CM_ "AUTOGENERATED FILE, DO NOT EDIT"

CM_ "Imported file _comma.dbc starts here"
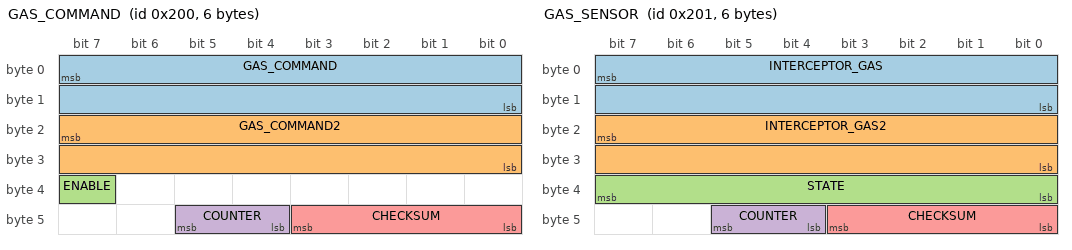
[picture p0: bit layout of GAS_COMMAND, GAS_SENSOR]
BO_ 512 GAS_COMMAND: 6 EON
 SG_ GAS_COMMAND : 7|16@0+ (0.253984064,-83.3) [0|1] "" INTERCEPTOR
 SG_ GAS_COMMAND2 : 23|16@0+ (0.126992032,-83.3) [0|1] "" INTERCEPTOR
 SG_ ENABLE : 39|1@0+ (1,0) [0|1] "" INTERCEPTOR
 SG_ COUNTER : 45|2@0+ (1,0) [0|3] "" INTERCEPTOR
 SG_ CHECKSUM : 43|4@0+ (1,0) [0|3] "" INTERCEPTOR

BO_ 513 GAS_SENSOR: 6 INTERCEPTOR
 SG_ INTERCEPTOR_GAS : 7|16@0+ (0.253984064,-83.3) [0|1] "" EON
 SG_ INTERCEPTOR_GAS2 : 23|16@0+ (0.126992032,-83.3) [0|1] "" EON
 SG_ STATE : 39|8@0+ (1,0) [0|255] "" EON
 SG_ COUNTER : 45|2@0+ (1,0) [0|3] "" EON
 SG_ CHECKSUM : 43|4@0+ (1,0) [0|3] "" EON

VAL_ 513 STATE 5 "FAULT_TIMEOUT" 4 "FAULT_STARTUP" 3 "FAULT_SCE" 2 "FAULT_SEND" 1 "FAULT_BAD_CHECKSUM" 0 "NO_FAULT" ;

CM_ "Imported file _honda_2017.dbc starts here"
VERSION ""

NS_ :

BU_: PCM MACC ABS EPS EON XXX

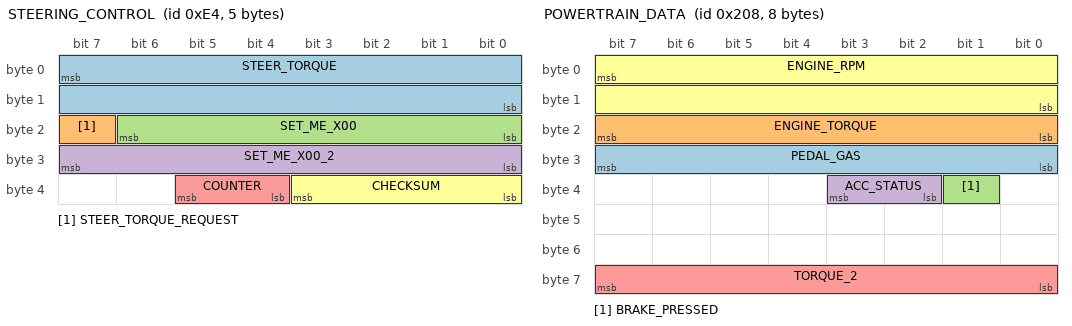
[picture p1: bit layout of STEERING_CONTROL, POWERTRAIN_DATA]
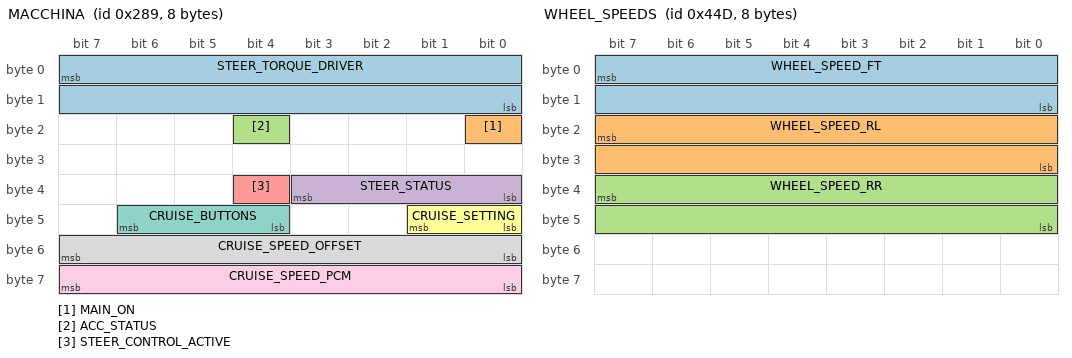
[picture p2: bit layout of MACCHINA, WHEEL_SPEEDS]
BO_ 228 STEERING_CONTROL: 5 ADAS
 SG_ STEER_TORQUE : 7|16@0- (1,0) [-3840|3840] "" EPS
 SG_ STEER_TORQUE_REQUEST : 23|1@0+ (1,0) [0|1] "" EPS
 SG_ SET_ME_X00 : 22|7@0+ (1,0) [0|127] "" EPS
 SG_ SET_ME_X00_2 : 31|8@0+ (1,0) [0|0] "" EPS
 SG_ COUNTER : 37|2@0+ (1,0) [0|3] "" EPS
 SG_ CHECKSUM : 35|4@0+ (1,0) [0|15] "" EPS

BO_ 520 POWERTRAIN_DATA: 8 PCM
 SG_ PEDAL_GAS : 24|8@1+ (1,0) [0|255] "" EON
 SG_ ENGINE_TORQUE : 23|8@0- (0.5,100) [0|255] "Nm" EON
 SG_ BRAKE_PRESSED : 33|1@0+ (1,0) [0|1] "" EON
 SG_ ACC_STATUS : 34|2@1+ (1,0) [0|3] "" EON
 SG_ TORQUE_2 : 56|8@1+ (0.5,100) [0|255] "" EON
 SG_ ENGINE_RPM : 7|16@0+ (0.15,0) [0|65535] "rpm" EON

 BO_ 649 MACCHINA: 8 MACC
 SG_ STEER_TORQUE_DRIVER : 7|16@0- (1,0) [-31000|31000] "" EON
 SG_ MAIN_ON : 16|1@0+ (1,0) [0|1] "" EON
 SG_ ACC_STATUS : 20|1@0+ (1,0) [0|1] "" EON
 SG_ STEER_STATUS : 35|4@0+ (1,0) [0|15] "" EON
 SG_ STEER_CONTROL_ACTIVE : 36|1@0+ (1,0) [0|1] "" EON
 SG_ CRUISE_SETTING: 41|2@0+ (1,0) [0|3] "" EON
 SG_ CRUISE_BUTTONS: 46|3@0+ (1,0) [0|7] "" EON
 SG_ CRUISE_SPEED_OFFSET: 55|8@0- (0.1,0) [-128|127] "kph" EON
 SG_ CRUISE_SPEED_PCM: 63|8@0+ (1,0) [0|255] "kph?" EON

BO_ 1101 WHEEL_SPEEDS: 8 PCM
 SG_ WHEEL_SPEED_FT : 7|16@0+ (0.01,0) [0|65535] "km/h" EON
 SG_ WHEEL_SPEED_RL : 23|16@0+ (0.01,0) [0|65535] "kph" EON
 SG_ WHEEL_SPEED_RR : 39|16@0+ (0.01,0) [0|65535] "kph" EON

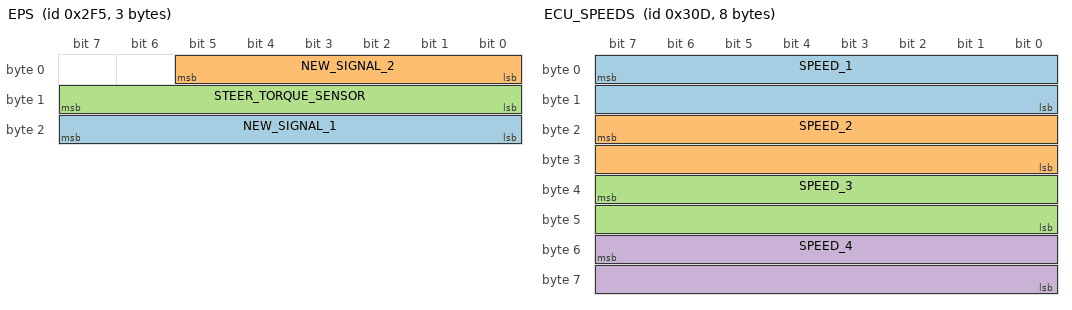
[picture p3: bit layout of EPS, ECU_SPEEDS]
BO_ 757 EPS: 3 EPS
 SG_ NEW_SIGNAL_1 : 23|8@0+ (1,0) [0|255] "" EON
 SG_ NEW_SIGNAL_2 : 0|6@1- (1,0) [0|3] "" EON
 SG_ STEER_TORQUE_SENSOR : 8|8@1- (1,0) [0|255] "Nm" EON

BO_ 781 ECU_SPEEDS: 8 PCM
 SG_ SPEED_1 : 7|16@0+ (0.01,0) [0|65535] "km/h" EON
 SG_ SPEED_2 : 23|16@0+ (0.01,0) [0|65535] "km/h" EON
 SG_ SPEED_3 : 39|16@0+ (0.01,0) [0|65535] "km/h" EON
 SG_ SPEED_4 : 55|16@0+ (0.01,0) [0|65535] "km/h" EON

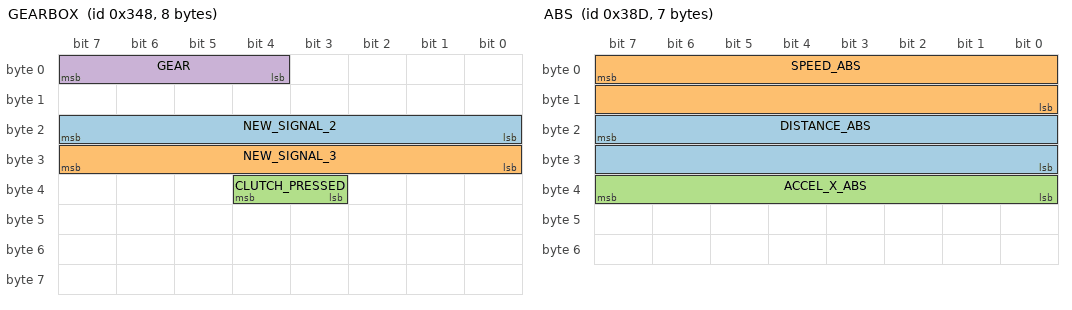
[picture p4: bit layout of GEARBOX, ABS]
BO_ 840 GEARBOX: 8 PCM
 SG_ NEW_SIGNAL_2 : 16|8@1+ (1,0) [0|255] "" XXX
 SG_ NEW_SIGNAL_3 : 24|8@1+ (1,0) [0|255] "" XXX
 SG_ CLUTCH_PRESSED : 36|2@0+ (1,0) [0|3] "" XXX
 SG_ GEAR : 7|4@0+ (1,0) [0|15] "" XXX

BO_ 909 ABS: 7 ABS
 SG_ DISTANCE_ABS : 23|16@0+ (0.1,0) [0|65535] "m" EON
 SG_ SPEED_ABS : 7|16@0+ (0.01,0) [0|65535] "kph" EON
 SG_ ACCEL_X_ABS : 39|8@0+ (0.08,-14) [0|65535] "m/s2" EON

BO_ 1042 CAR: 8 PCM
 SG_ BRAKE_PRESSED : 5|1@0+ (1,0) [0|1] "" EON

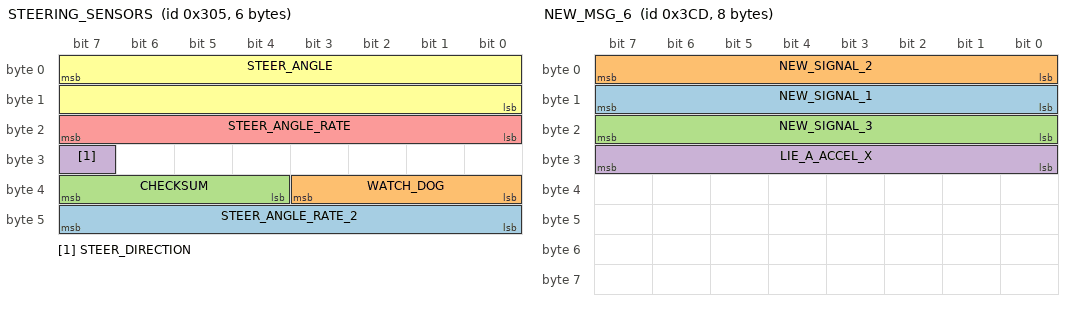
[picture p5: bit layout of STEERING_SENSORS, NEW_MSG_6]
BO_ 773 STEERING_SENSORS: 6 EPS
 SG_ STEER_ANGLE_RATE_2 : 40|8@1+ (1,0) [0|255] "" EON
 SG_ WATCH_DOG : 32|4@1+ (1,0) [0|15] "" XXX
 SG_ CHECKSUM : 39|4@0+ (1,0) [0|3] "" XXX
 SG_ STEER_DIRECTION : 31|1@1+ (1,0) [0|255] "" EON
 SG_ STEER_ANGLE_RATE : 16|8@1+ (1,0) [0|255] "" EON
 SG_ STEER_ANGLE : 7|16@0- (0.1,0) [0|65535] "" EON

BO_ 973 NEW_MSG_6: 8 XXX
 SG_ NEW_SIGNAL_1 : 8|8@1- (1,0) [0|255] "" XXX
 SG_ NEW_SIGNAL_2 : 0|8@1+ (1,0) [0|255] "" XXX
 SG_ NEW_SIGNAL_3 : 16|8@1+ (1,0) [0|255] "" XXX
 SG_ LIE_A_ACCEL_X : 24|8@1- (1,0) [0|255] "" XXX

BO_ 1294 CRUISE: 8 XXX
 SG_ LIMITER : 0|8@1+ (1,0) [0|255] "" XXX

CM_ SG_ 520 BRAKE_PRESSED "0: brake off, 1: brake on";
CM_ SG_ 520 ACC_STATUS "00: off, 01: reprise pédale, 10: ON";
CM_ SG_ 840 GEAR "0: débrayé ou point mort, 1: première, 2: deuxième, 3: troisième, 4: quatrième, 5: cinquième, 9: marche arrière";
CM_ SG_ 1101 WHEEL_SPEED_FT "vitesse moyenne des deux roues avant";
VAL_ 840 GEAR 9 "R" 5 "5eme" 4 "4eme" 3 "3eme" 2 "2nd" 1 "1ere" 0 "Pt_mort" ;
